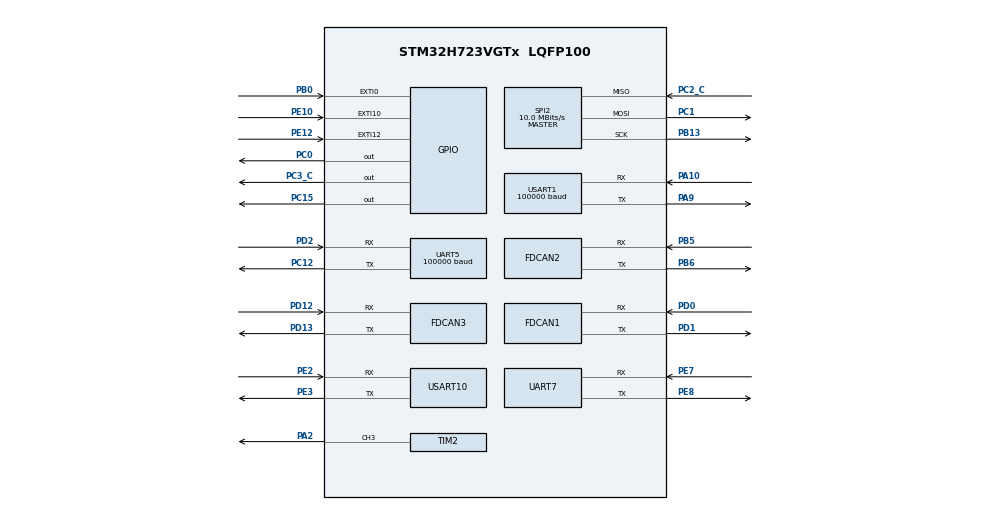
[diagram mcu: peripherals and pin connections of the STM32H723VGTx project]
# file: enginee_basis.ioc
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CORTEX_M7.default_mode_Activation=0
Dma.Request0=UART5_RX
Dma.Request1=USART1_RX
Dma.Request2=SPI2_RX
Dma.Request3=SPI2_TX
Dma.Request4=USART10_RX
Dma.Request5=USART10_TX
Dma.Request6=UART7_RX
Dma.Request7=UART7_TX
Dma.SPI2_RX.2.Direction=DMA_PERIPH_TO_MEMORY
Dma.SPI2_RX.2.EventEnable=DISABLE
Dma.SPI2_RX.2.FIFOMode=DMA_FIFOMODE_DISABLE
Dma.SPI2_RX.2.Instance=DMA1_Stream0
Dma.SPI2_RX.2.MemDataAlignment=DMA_MDATAALIGN_BYTE
Dma.SPI2_RX.2.MemInc=DMA_MINC_ENABLE
Dma.SPI2_RX.2.Mode=DMA_NORMAL
Dma.SPI2_RX.2.PeriphDataAlignment=DMA_PDATAALIGN_BYTE
Dma.SPI2_RX.2.PeriphInc=DMA_PINC_DISABLE
Dma.SPI2_RX.2.Polarity=HAL_DMAMUX_REQ_GEN_RISING
Dma.SPI2_RX.2.Priority=DMA_PRIORITY_LOW
Dma.SPI2_RX.2.RequestNumber=1
Dma.SPI2_RX.2.SignalID=NONE
Dma.SPI2_RX.2.SyncEnable=DISABLE
Dma.SPI2_RX.2.SyncPolarity=HAL_DMAMUX_SYNC_NO_EVENT
Dma.SPI2_RX.2.SyncRequestNumber=1
Dma.SPI2_RX.2.SyncSignalID=NONE
Dma.SPI2_TX.3.Direction=DMA_MEMORY_TO_PERIPH
Dma.SPI2_TX.3.EventEnable=DISABLE
Dma.SPI2_TX.3.FIFOMode=DMA_FIFOMODE_DISABLE
Dma.SPI2_TX.3.Instance=DMA1_Stream1
Dma.SPI2_TX.3.MemDataAlignment=DMA_MDATAALIGN_BYTE
Dma.SPI2_TX.3.MemInc=DMA_MINC_ENABLE
Dma.SPI2_TX.3.Mode=DMA_NORMAL
Dma.SPI2_TX.3.PeriphDataAlignment=DMA_PDATAALIGN_BYTE
Dma.SPI2_TX.3.PeriphInc=DMA_PINC_DISABLE
Dma.SPI2_TX.3.Polarity=HAL_DMAMUX_REQ_GEN_RISING
Dma.SPI2_TX.3.Priority=DMA_PRIORITY_LOW
Dma.SPI2_TX.3.RequestNumber=1
Dma.SPI2_TX.3.SignalID=NONE
Dma.SPI2_TX.3.SyncEnable=DISABLE
Dma.SPI2_TX.3.SyncPolarity=HAL_DMAMUX_SYNC_NO_EVENT
Dma.SPI2_TX.3.SyncRequestNumber=1
Dma.SPI2_TX.3.SyncSignalID=NONE
Dma.UART5_RX.0.Direction=DMA_PERIPH_TO_MEMORY
Dma.UART5_RX.0.EventEnable=DISABLE
Dma.UART5_RX.0.FIFOMode=DMA_FIFOMODE_DISABLE
Dma.UART5_RX.0.Instance=DMA1_Stream2
Dma.UART5_RX.0.MemDataAlignment=DMA_MDATAALIGN_BYTE
Dma.UART5_RX.0.MemInc=DMA_MINC_ENABLE
Dma.UART5_RX.0.Mode=DMA_NORMAL
Dma.UART5_RX.0.PeriphDataAlignment=DMA_PDATAALIGN_BYTE
Dma.UART5_RX.0.PeriphInc=DMA_PINC_DISABLE
Dma.UART5_RX.0.Polarity=HAL_DMAMUX_REQ_GEN_RISING
Dma.UART5_RX.0.Priority=DMA_PRIORITY_LOW
Dma.UART5_RX.0.RequestNumber=1
Dma.UART5_RX.0.SignalID=NONE
Dma.UART5_RX.0.SyncEnable=DISABLE
Dma.UART5_RX.0.SyncPolarity=HAL_DMAMUX_SYNC_NO_EVENT
Dma.UART5_RX.0.SyncRequestNumber=1
Dma.UART5_RX.0.SyncSignalID=NONE
Dma.UART7_RX.6.Direction=DMA_PERIPH_TO_MEMORY
Dma.UART7_RX.6.EventEnable=DISABLE
Dma.UART7_RX.6.FIFOMode=DMA_FIFOMODE_DISABLE
Dma.UART7_RX.6.Instance=DMA1_Stream6
Dma.UART7_RX.6.MemDataAlignment=DMA_MDATAALIGN_BYTE
Dma.UART7_RX.6.MemInc=DMA_MINC_ENABLE
Dma.UART7_RX.6.Mode=DMA_NORMAL
Dma.UART7_RX.6.PeriphDataAlignment=DMA_PDATAALIGN_BYTE
Dma.UART7_RX.6.PeriphInc=DMA_PINC_DISABLE
Dma.UART7_RX.6.Polarity=HAL_DMAMUX_REQ_GEN_RISING
Dma.UART7_RX.6.Priority=DMA_PRIORITY_LOW
Dma.UART7_RX.6.RequestNumber=1
Dma.UART7_RX.6.SignalID=NONE
Dma.UART7_RX.6.SyncEnable=DISABLE
Dma.UART7_RX.6.SyncPolarity=HAL_DMAMUX_SYNC_NO_EVENT
Dma.UART7_RX.6.SyncRequestNumber=1
Dma.UART7_RX.6.SyncSignalID=NONE
Dma.UART7_TX.7.Direction=DMA_MEMORY_TO_PERIPH
Dma.UART7_TX.7.EventEnable=DISABLE
Dma.UART7_TX.7.FIFOMode=DMA_FIFOMODE_DISABLE
Dma.UART7_TX.7.Instance=DMA1_Stream7
Dma.UART7_TX.7.MemDataAlignment=DMA_MDATAALIGN_BYTE
Dma.UART7_TX.7.MemInc=DMA_MINC_ENABLE
Dma.UART7_TX.7.Mode=DMA_NORMAL
Dma.UART7_TX.7.PeriphDataAlignment=DMA_PDATAALIGN_BYTE
Dma.UART7_TX.7.PeriphInc=DMA_PINC_DISABLE
Dma.UART7_TX.7.Polarity=HAL_DMAMUX_REQ_GEN_RISING
Dma.UART7_TX.7.Priority=DMA_PRIORITY_LOW
Dma.UART7_TX.7.RequestNumber=1
Dma.UART7_TX.7.SignalID=NONE
Dma.UART7_TX.7.SyncEnable=DISABLE
Dma.UART7_TX.7.SyncPolarity=HAL_DMAMUX_SYNC_NO_EVENT
Dma.UART7_TX.7.SyncRequestNumber=1
Dma.UART7_TX.7.SyncSignalID=NONE
Dma.USART10_RX.4.Direction=DMA_PERIPH_TO_MEMORY
Dma.USART10_RX.4.EventEnable=DISABLE
Dma.USART10_RX.4.FIFOMode=DMA_FIFOMODE_DISABLE
Dma.USART10_RX.4.Instance=DMA1_Stream4
Dma.USART10_RX.4.MemDataAlignment=DMA_MDATAALIGN_BYTE
Dma.USART10_RX.4.MemInc=DMA_MINC_ENABLE
Dma.USART10_RX.4.Mode=DMA_NORMAL
Dma.USART10_RX.4.PeriphDataAlignment=DMA_PDATAALIGN_BYTE
Dma.USART10_RX.4.PeriphInc=DMA_PINC_DISABLE
Dma.USART10_RX.4.Polarity=HAL_DMAMUX_REQ_GEN_RISING
Dma.USART10_RX.4.Priority=DMA_PRIORITY_LOW
Dma.USART10_RX.4.RequestNumber=1
Dma.USART10_RX.4.SignalID=NONE
Dma.USART10_RX.4.SyncEnable=DISABLE
Dma.USART10_RX.4.SyncPolarity=HAL_DMAMUX_SYNC_NO_EVENT
Dma.USART10_RX.4.SyncRequestNumber=1
Dma.USART10_RX.4.SyncSignalID=NONE
Dma.USART10_TX.5.Direction=DMA_MEMORY_TO_PERIPH
Dma.USART10_TX.5.EventEnable=DISABLE
Dma.USART10_TX.5.FIFOMode=DMA_FIFOMODE_DISABLE
Dma.USART10_TX.5.Instance=DMA1_Stream5
Dma.USART10_TX.5.MemDataAlignment=DMA_MDATAALIGN_BYTE
Dma.USART10_TX.5.MemInc=DMA_MINC_ENABLE
Dma.USART10_TX.5.Mode=DMA_NORMAL
Dma.USART10_TX.5.PeriphDataAlignment=DMA_PDATAALIGN_BYTE
Dma.USART10_TX.5.PeriphInc=DMA_PINC_DISABLE
Dma.USART10_TX.5.Polarity=HAL_DMAMUX_REQ_GEN_RISING
Dma.USART10_TX.5.Priority=DMA_PRIORITY_LOW
Dma.USART10_TX.5.RequestNumber=1
Dma.USART10_TX.5.SignalID=NONE
Dma.USART10_TX.5.SyncEnable=DISABLE
Dma.USART10_TX.5.SyncPolarity=HAL_DMAMUX_SYNC_NO_EVENT
Dma.USART10_TX.5.SyncRequestNumber=1
Dma.USART10_TX.5.SyncSignalID=NONE
Dma.USART1_RX.1.Direction=DMA_PERIPH_TO_MEMORY
Dma.USART1_RX.1.EventEnable=DISABLE
Dma.USART1_RX.1.FIFOMode=DMA_FIFOMODE_DISABLE
Dma.USART1_RX.1.Instance=DMA1_Stream3
Dma.USART1_RX.1.MemDataAlignment=DMA_MDATAALIGN_BYTE
Dma.USART1_RX.1.MemInc=DMA_MINC_ENABLE
Dma.USART1_RX.1.Mode=DMA_NORMAL
Dma.USART1_RX.1.PeriphDataAlignment=DMA_PDATAALIGN_BYTE
Dma.USART1_RX.1.PeriphInc=DMA_PINC_DISABLE
Dma.USART1_RX.1.Polarity=HAL_DMAMUX_REQ_GEN_RISING
Dma.USART1_RX.1.Priority=DMA_PRIORITY_LOW
Dma.USART1_RX.1.RequestNumber=1
Dma.USART1_RX.1.SignalID=NONE
Dma.USART1_RX.1.SyncEnable=DISABLE
Dma.USART1_RX.1.SyncPolarity=HAL_DMAMUX_SYNC_NO_EVENT
Dma.USART1_RX.1.SyncRequestNumber=1
Dma.USART1_RX.1.SyncSignalID=NONE
FDCAN1.AutoRetransmission=ENABLE
FDCAN1.CalculateBaudRateNominal=1000000
FDCAN1.CalculateTimeBitNominal=1000
FDCAN1.CalculateTimeQuantumNominal=12.5
FDCAN1.DataPrescaler=2
FDCAN1.DataSyncJumpWidth=8
FDCAN1.DataTimeSeg1=31
FDCAN1.DataTimeSeg2=8
FDCAN1.ExtFiltersNbr=0
FDCAN1.MessageRAMOffset=0
FDCAN1.NominalPrescaler=1
FDCAN1.NominalSyncJumpWidth=20
FDCAN1.NominalTimeSeg1=59
FDCAN1.NominalTimeSeg2=20
FDCAN1.ProtocolException=ENABLE
FDCAN1.RxFifo0ElmtsNbr=4
FDCAN1.StdFiltersNbr=0
FDCAN1.TxFifoQueueElmtsNbr=4
FDCAN2.AutoRetransmission=ENABLE
FDCAN2.CalculateBaudRateNominal=1000000
FDCAN2.CalculateTimeBitNominal=1000
FDCAN2.CalculateTimeQuantumNominal=12.5
FDCAN2.DataPrescaler=2
FDCAN2.DataSyncJumpWidth=8
FDCAN2.DataTimeSeg1=31
FDCAN2.DataTimeSeg2=8
FDCAN2.ExtFiltersNbr=0
FDCAN2.MessageRAMOffset=853
FDCAN2.NominalPrescaler=1
FDCAN2.NominalSyncJumpWidth=20
FDCAN2.NominalTimeSeg1=59
FDCAN2.NominalTimeSeg2=20
FDCAN2.ProtocolException=ENABLE
FDCAN2.RxFifo0ElmtsNbr=8
FDCAN2.StdFiltersNbr=0
FDCAN2.TxFifoQueueElmtsNbr=8
FDCAN3.AutoRetransmission=ENABLE
FDCAN3.CalculateBaudRateNominal=1000000
FDCAN3.CalculateTimeBitNominal=1000
FDCAN3.CalculateTimeQuantumNominal=12.5
FDCAN3.DataPrescaler=2
FDCAN3.DataSyncJumpWidth=8
FDCAN3.DataTimeSeg1=31
FDCAN3.DataTimeSeg2=8
FDCAN3.ExtFiltersNbr=0
FDCAN3.MessageRAMOffset=2006
FDCAN3.NominalPrescaler=1
FDCAN3.NominalSyncJumpWidth=20
FDCAN3.NominalTimeSeg1=59
FDCAN3.NominalTimeSeg2=20
FDCAN3.ProtocolException=ENABLE
FDCAN3.RxFifo0ElmtsNbr=6
FDCAN3.StdFiltersNbr=0
FDCAN3.TxFifoQueueElmtsNbr=6
Mcu.Family=STM32H7
Mcu.Name=STM32H723VGTx
Mcu.Package=LQFP100
NVIC.DMA1_Stream0_IRQn=true\:0\:0\:false\:false\:true\:false\:true\:true
NVIC.DMA1_Stream1_IRQn=true\:0\:0\:false\:false\:true\:false\:true\:true
NVIC.DMA1_Stream2_IRQn=true\:0\:0\:false\:false\:true\:false\:true\:true
NVIC.DMA1_Stream3_IRQn=true\:0\:0\:false\:false\:true\:false\:true\:true
NVIC.DMA1_Stream4_IRQn=true\:0\:0\:false\:false\:true\:false\:true\:true
NVIC.DMA1_Stream5_IRQn=true\:0\:0\:false\:false\:true\:false\:true\:true
NVIC.DMA1_Stream6_IRQn=true\:0\:0\:false\:false\:true\:false\:true\:true
NVIC.DMA1_Stream7_IRQn=true\:0\:0\:false\:false\:true\:false\:true\:true
NVIC.EXTI0_IRQn=true\:0\:0\:false\:false\:true\:true\:true\:true
NVIC.EXTI15_10_IRQn=true\:0\:0\:false\:false\:true\:true\:true\:true
NVIC.FDCAN1_IT0_IRQn=true\:2\:0\:true\:false\:true\:true\:true\:true
NVIC.FDCAN2_IT0_IRQn=true\:2\:0\:true\:false\:true\:true\:true\:true
NVIC.FDCAN3_IT0_IRQn=true\:0\:0\:false\:false\:true\:true\:true\:true
NVIC.PriorityGroup=NVIC_PRIORITYGROUP_4
NVIC.SPI2_IRQn=true\:0\:0\:false\:false\:true\:true\:true\:true
NVIC.TIM1_UP_IRQn=true\:0\:0\:false\:false\:true\:true\:true\:true
NVIC.UART5_IRQn=true\:0\:0\:false\:false\:true\:true\:true\:true
NVIC.UART7_IRQn=true\:0\:0\:false\:false\:true\:true\:true\:true
NVIC.USART10_IRQn=true\:0\:0\:false\:false\:true\:true\:true\:true
NVIC.USART1_IRQn=true\:0\:0\:false\:false\:true\:true\:true\:true
PA10.Mode=Asynchronous
PA10.Signal=USART1_RX
PA2.Signal=S_TIM2_CH3
PA9.Mode=Asynchronous
PA9.Signal=USART1_TX
PB0.GPIO_PuPd=GPIO_PULLDOWN
PB0.Signal=GPXTI0
PB13.GPIO_Speed=GPIO_SPEED_FREQ_LOW
PB13.Mode=Full_Duplex_Master
PB13.Signal=SPI2_SCK
PB5.Mode=FDCAN_Activate
PB5.Signal=FDCAN2_RX
PB6.Mode=FDCAN_Activate
PB6.Signal=FDCAN2_TX
PC0.GPIO_ModeDefaultOutputPP=GPIO_MODE_OUTPUT_PP
PC0.GPIO_PuPd=GPIO_PULLDOWN
PC0.GPIO_Speed=GPIO_SPEED_FREQ_VERY_HIGH
PC0.PinState=GPIO_PIN_SET
PC0.Signal=GPIO_Output
PC1.GPIO_Speed=GPIO_SPEED_FREQ_LOW
PC1.Mode=Full_Duplex_Master
PC1.Signal=SPI2_MOSI
PC12.Mode=Asynchronous
PC12.Signal=UART5_TX
PC15-OSC32_OUT.PinState=GPIO_PIN_SET
PC15-OSC32_OUT.Signal=GPIO_Output
PC2_C.GPIO_Speed=GPIO_SPEED_FREQ_LOW
PC2_C.Mode=Full_Duplex_Master
PC2_C.Signal=SPI2_MISO
PC3_C.GPIO_ModeDefaultOutputPP=GPIO_MODE_OUTPUT_PP
PC3_C.GPIO_PuPd=GPIO_PULLDOWN
PC3_C.GPIO_Speed=GPIO_SPEED_FREQ_VERY_HIGH
PC3_C.PinState=GPIO_PIN_SET
PC3_C.Signal=GPIO_Output
PD0.Mode=FDCAN_Activate
PD0.Signal=FDCAN1_RX
PD1.Mode=FDCAN_Activate
PD1.Signal=FDCAN1_TX
PD12.Mode=FDCAN_Activate
PD12.Signal=FDCAN3_RX
PD13.Mode=FDCAN_Activate
PD13.Signal=FDCAN3_TX
PD2.Mode=Asynchronous
PD2.Signal=UART5_RX
PE10.GPIO_PuPd=GPIO_NOPULL
PE10.Signal=GPXTI10
PE12.GPIO_PuPd=GPIO_NOPULL
PE12.Signal=GPXTI12
PE2.Mode=Asynchronous
PE2.Signal=USART10_RX
PE3.Mode=Asynchronous
PE3.Signal=USART10_TX
PE7.Mode=Asynchronous
PE7.Signal=UART7_RX
PE8.Mode=Asynchronous
PE8.Signal=UART7_TX
PH0-OSC_IN.Mode=HSE-External-Oscillator
PH0-OSC_IN.Signal=RCC_OSC_IN
PH1-OSC_OUT.Mode=HSE-External-Oscillator
PH1-OSC_OUT.Signal=RCC_OSC_OUT
ProjectManager.HeapSize=0x800
ProjectManager.StackSize=0x800
ProjectManager.TargetToolchain=MDK-ARM V5.32
RCC.ADCFreq_Value=100000000
RCC.APB1Freq_Value=120000000
RCC.APB2Freq_Value=120000000
RCC.APB3Freq_Value=120000000
RCC.APB4Freq_Value=120000000
RCC.CortexFreq_Value=480000000
RCC.D1PPRE=RCC_APB3_DIV2
RCC.D2PPRE1=RCC_APB1_DIV2
RCC.D2PPRE2=RCC_APB2_DIV2
RCC.D3PPRE=RCC_APB4_DIV2
RCC.DIVM1=2
RCC.DIVM2=24
RCC.DIVN1=40
RCC.DIVN2=200
RCC.DIVP1=1
RCC.DIVQ1=6
RCC.HCLKFreq_Value=240000000
RCC.HPRE=RCC_HCLK_DIV2
RCC.HSE_VALUE=24000000
RCC.PLL2FRACN=0
RCC.PLL3FRACN=0
RCC.PLLFRACN=0
RCC.PLLSourceVirtual=RCC_PLLSOURCE_HSE
RCC.SYSCLKFreq_VALUE=480000000
RCC.SYSCLKSource=RCC_SYSCLKSOURCE_PLLCLK
RCC.USBFreq_Value=80000000
SH.S_TIM2_CH3.0=TIM2_CH3,PWM Generation3 CH3
SPI2.BaudRatePrescaler=SPI_BAUDRATEPRESCALER_8
SPI2.CLKPhase=SPI_PHASE_2EDGE
SPI2.CLKPolarity=SPI_POLARITY_HIGH
SPI2.CalculateBaudRate=10.0 MBits/s
SPI2.DataSize=SPI_DATASIZE_8BIT
SPI2.Direction=SPI_DIRECTION_2LINES
SPI2.Mode=SPI_MODE_MASTER
SPI2.VirtualType=VM_MASTER
TIM1.Period=999
TIM1.Prescaler=239
TIM2.AutoReloadPreload=TIM_AUTORELOAD_PRELOAD_ENABLE
TIM2.Channel-PWM\ Generation3\ CH3=TIM_CHANNEL_3
TIM2.Period=19999
TIM2.Prescaler=239
TIM3.Period=999
TIM3.Prescaler=239
UART5.BaudRate=100000
UART5.Mode=MODE_TX_RX
UART5.Parity=PARITY_EVEN
UART5.WordLength=WORDLENGTH_9B
USART1.AutoBaudRateEnableParam=UART_ADVFEATURE_AUTOBAUDRATE_DISABLE
USART1.BaudRate=100000
USART1.Parity=PARITY_EVEN
USART1.VirtualMode-Asynchronous=VM_ASYNC
USART10.FIFOMode=FIFOMODE_ENABLE
USART10.VirtualMode=VM_ASYNC
VP_MEMORYMAP_VS_MEMORYMAP.Mode=CurAppReg
VP_TIM1_VS_ClockSourceINT.Mode=Internal
VP_TIM2_VS_ClockSourceINT.Mode=Internal
VP_TIM3_VS_ClockSourceINT.Mode=Internal
board=custom

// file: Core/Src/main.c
/* USER CODE BEGIN Header */
/**
  ******************************************************************************
  * @file           : main.c
  * @brief          : Main program body
  ******************************************************************************
  * @attention
  *
  * Copyright (c) 2026 STMicroelectronics.
  * All rights reserved.
  *
  * This software is licensed under terms that can be found in the LICENSE file
  * in the root directory of this software component.
  * If no LICENSE file comes with this software, it is provided AS-IS.
  *
  ******************************************************************************
  */
/* USER CODE END Header */
#include "main.h"
#include "dma.h"
#include "fdcan.h"
#include "spi.h"
#include "tim.h"
#include "usart.h"
#include "gpio.h"

/* USER CODE BEGIN Includes */

#include "Init_engine_car.h"

/* USER CODE END Includes */

void SystemClock_Config(void);

int main(void)
{

  /* MCU Configuration--------------------------------------------------------*/

  /* Reset of all peripherals, Initializes the Flash interface and the Systick. */
  HAL_Init();

  /* Configure the system clock */
  SystemClock_Config();

  /* Initialize all configured peripherals */
  MX_GPIO_Init();
  MX_DMA_Init();
  MX_FDCAN1_Init();
  MX_TIM2_Init();
  MX_UART5_Init();
  MX_FDCAN2_Init();
  MX_FDCAN3_Init();
  MX_USART1_UART_Init();
  MX_TIM1_Init();
  MX_SPI2_Init();
  MX_USART10_UART_Init();
  MX_UART7_Init();
  MX_TIM3_Init();
  /* USER CODE BEGIN 2 */

//	mechanical_arm_init();

  /* USER CODE END 2 */

  /* Infinite loop */
  /* USER CODE BEGIN WHILE */

	cali_param_init();
	while(BMI088_init())
	{
		HAL_Delay(1);
	}
		Init_engine_car();
	while (1)
	{

	}

    /* USER CODE END WHILE */

}

void SystemClock_Config(void)
{
  RCC_OscInitTypeDef RCC_OscInitStruct = {0};
  RCC_ClkInitTypeDef RCC_ClkInitStruct = {0};

  /** Supply configuration update enable
  */
  HAL_PWREx_ConfigSupply(PWR_LDO_SUPPLY);

  /** Configure the main internal regulator output voltage
  */
  __HAL_PWR_VOLTAGESCALING_CONFIG(PWR_REGULATOR_VOLTAGE_SCALE0);

  while(!__HAL_PWR_GET_FLAG(PWR_FLAG_VOSRDY)) {}

  /** Initializes the RCC Oscillators according to the specified parameters
  * in the RCC_OscInitTypeDef structure.
  */
  RCC_OscInitStruct.OscillatorType = RCC_OSCILLATORTYPE_HSE;
  RCC_OscInitStruct.HSEState = RCC_HSE_ON;
  RCC_OscInitStruct.PLL.PLLState = RCC_PLL_ON;
  RCC_OscInitStruct.PLL.PLLSource = RCC_PLLSOURCE_HSE;
  RCC_OscInitStruct.PLL.PLLM = 2;
  RCC_OscInitStruct.PLL.PLLN = 40;
  RCC_OscInitStruct.PLL.PLLP = 1;
  RCC_OscInitStruct.PLL.PLLQ = 6;
  RCC_OscInitStruct.PLL.PLLR = 2;
  RCC_OscInitStruct.PLL.PLLRGE = RCC_PLL1VCIRANGE_3;
  RCC_OscInitStruct.PLL.PLLVCOSEL = RCC_PLL1VCOWIDE;
  RCC_OscInitStruct.PLL.PLLFRACN = 0;
  if (HAL_RCC_OscConfig(&RCC_OscInitStruct) != HAL_OK)
  {
    Error_Handler();
  }

  /** Initializes the CPU, AHB and APB buses clocks
  */
  RCC_ClkInitStruct.ClockType = RCC_CLOCKTYPE_HCLK|RCC_CLOCKTYPE_SYSCLK
                              |RCC_CLOCKTYPE_PCLK1|RCC_CLOCKTYPE_PCLK2
                              |RCC_CLOCKTYPE_D3PCLK1|RCC_CLOCKTYPE_D1PCLK1;
  RCC_ClkInitStruct.SYSCLKSource = RCC_SYSCLKSOURCE_PLLCLK;
  RCC_ClkInitStruct.SYSCLKDivider = RCC_SYSCLK_DIV1;
  RCC_ClkInitStruct.AHBCLKDivider = RCC_HCLK_DIV2;
  RCC_ClkInitStruct.APB3CLKDivider = RCC_APB3_DIV2;
  RCC_ClkInitStruct.APB1CLKDivider = RCC_APB1_DIV2;
  RCC_ClkInitStruct.APB2CLKDivider = RCC_APB2_DIV2;
  RCC_ClkInitStruct.APB4CLKDivider = RCC_APB4_DIV2;

  if (HAL_RCC_ClockConfig(&RCC_ClkInitStruct, FLASH_LATENCY_3) != HAL_OK)
  {
    Error_Handler();
  }
}

void Error_Handler(void)
{
  __disable_irq();
  while (1)
  {
  }
}
